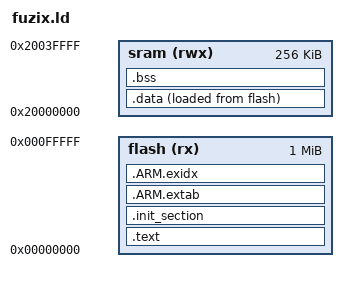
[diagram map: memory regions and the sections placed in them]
STARTUP(crt0.o)
OUTPUT_ARCH(arm)

SEARCH_DIR(.)

MEMORY
{
  flash (rx) : ORIGIN = 0x00000000, LENGTH = 1M
  sram (rwx) : ORIGIN = 0x20000000, LENGTH = 256K
}

EXTERN(_vectors)
ENTRY(_stext)

SECTIONS
{
    .text : {
        _stext = ABSOLUTE(.);
        *(.vectors)
        *(.text .text.*)
        *(.fixup)
        *(.gnu.warning)
        *(.rodata .rodata.*)
        *(.gnu.linkonce.t.*)
        *(.glue_7)
        *(.glue_7t)
        *(.got)
        *(.gcc_except_table)
        *(.gnu.linkonce.r.*)
        _etext = ABSOLUTE(.);
    } > flash

    .init_section : ALIGN(4) {
        _sinit = ABSOLUTE(.);
        *(.init_array .init_array.*)
        _einit = ABSOLUTE(.);
    } > flash

    .ARM.extab : ALIGN(4) {
        *(.ARM.extab*)
    } > flash

    .ARM.exidx : ALIGN(4) {
        __exidx_start = ABSOLUTE(.);
        *(.ARM.exidx*)
        __exidx_end = ABSOLUTE(.);
    } > flash

    _eronly = ABSOLUTE(.);

    .data : ALIGN(4) {
        _sdata = ABSOLUTE(.);
        *(.data .data.*)
        *(.gnu.linkonce.d.*)
        CONSTRUCTORS
        . = ALIGN(4);
        _edata = ABSOLUTE(.);
    } > sram AT > flash

    .bss : ALIGN(4) {
        _sbss = ABSOLUTE(.);
        *(.bss .bss.*)
        *(.gnu.linkonce.b.*)
        *(COMMON)
        . = ALIGN(4);
        _ebss = ABSOLUTE(.);
    } > sram
}
